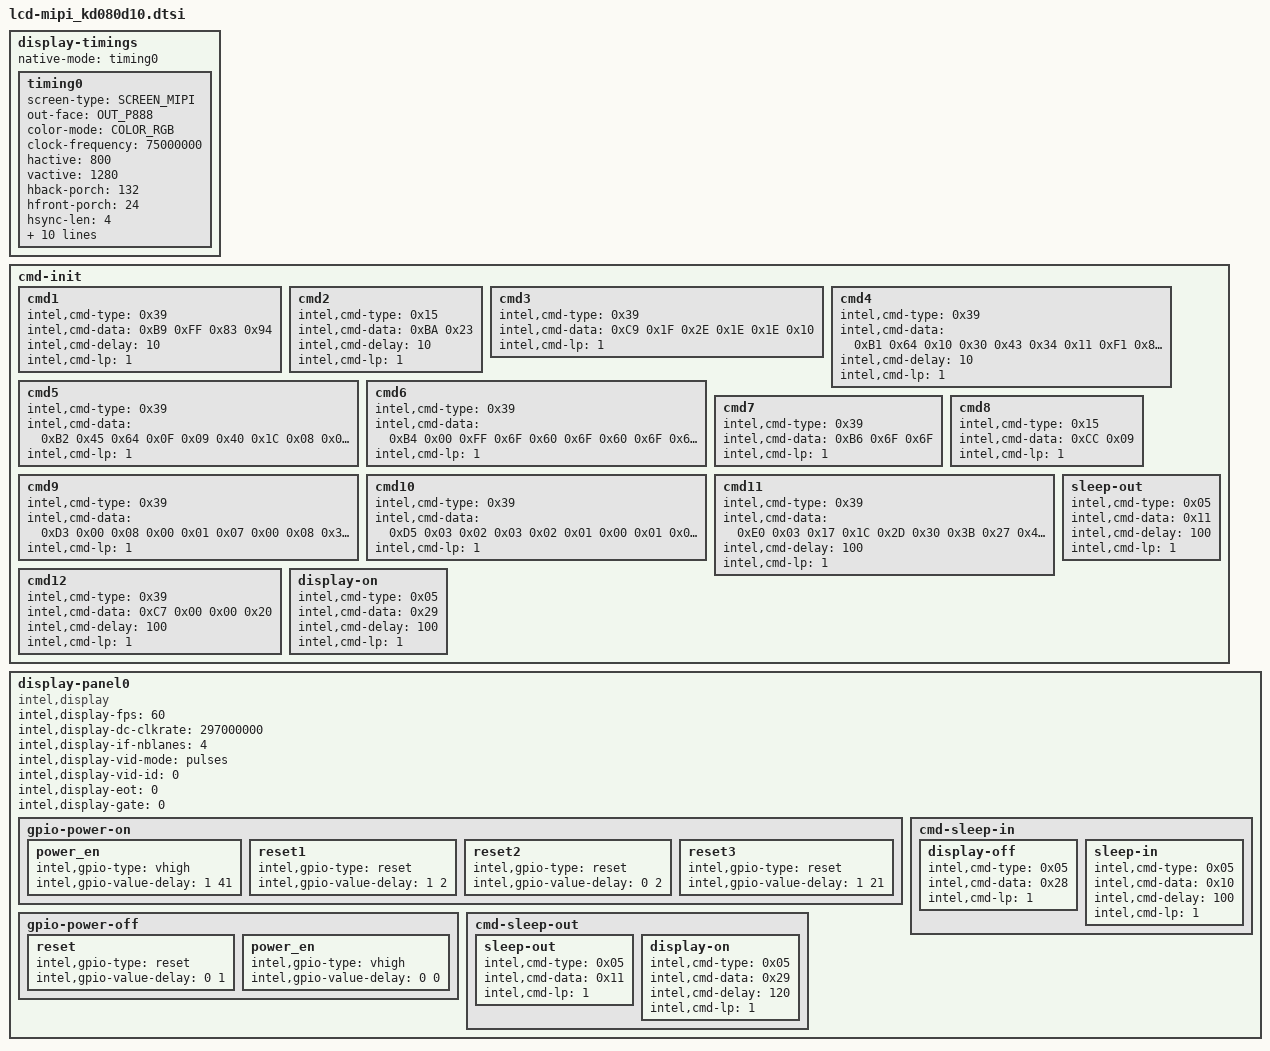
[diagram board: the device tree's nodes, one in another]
/*
 * definition at "include/dt-bindings/sofiafb/sofia_fb.h"
 */

display-timings {
	native-mode = <&timing0>;
	timing0: timing0 {
		screen-type = <SCREEN_MIPI>;
		out-face    = <OUT_P888>;
		color-mode = <COLOR_RGB>;
			clock-frequency = <75000000>;
			hactive = <800>;
			vactive = <1280>;
			hback-porch = <132>;
			hfront-porch = <24>;
			hsync-len = <4>;
			vback-porch = <8>;
			vfront-porch = <8>;
		vsync-len = <4>;
		hsync-active = <0>;
		vsync-active = <0>;
		de-active = <0>;
		pixelclk-active = <0>;
		swap-rb = <0>;
		swap-rg = <0>;
		swap-gb = <0>;
	};
};
		cmd-init {
			cmd1 {
				intel,cmd-type = <0x39>;
				intel,cmd-data = <0xB9 0xFF 0x83 0x94>;
				intel,cmd-delay = <10>;
				intel,cmd-lp = <1>;
			};
						cmd2 {
				intel,cmd-type = <0x15>;
				intel,cmd-data = <0xBA 0x23>;
				intel,cmd-delay = <10>;
				intel,cmd-lp = <1>;
			};
						cmd3 {
				intel,cmd-type = <0x39>;
				intel,cmd-data = <0xC9 0x1F 0x2E 0x1E 0x1E 0x10>;
				intel,cmd-lp = <1>;
			};
						cmd4 {
				intel,cmd-type = <0x39>;
				intel,cmd-data = <0xB1 0x64 0x10 0x30 0x43 0x34 0x11 0xF1 0x81 0x70 0xD9 0x34 0x80 0xC0 0xD2 0x41>;
				intel,cmd-delay = <10>;
				intel,cmd-lp = <1>;
			};
						cmd5 {
				intel,cmd-type = <0x39>;
				intel,cmd-data = <0xB2 0x45 0x64 0x0F 0x09 0x40 0x1C 0x08 0x08 0x1C 0x4D 0x00 0x00>;
				intel,cmd-lp = <1>;
			};
						cmd6 {
				intel,cmd-type = <0x39>;
				intel,cmd-data = <0xB4 0x00 0xFF 0x6F 0x60 0x6F 0x60 0x6F 0x60 0x01 0x6E 0x0F 0x6E 0x6F 0x60 0x6F 0x60 0x6F 0x60 0x01 0x6E 0x0F 0x6E>;
				intel,cmd-lp = <1>;
			};
						cmd7 {
				intel,cmd-type = <0x39>;
				intel,cmd-data = <0xB6 0x6F 0x6F>;
				intel,cmd-lp = <1>;
			};
						cmd8 {
				intel,cmd-type = <0x15>;
				intel,cmd-data = <0xCC 0x09>;
				intel,cmd-lp = <1>;
			};
						cmd9 {
				intel,cmd-type = <0x39>;
				intel,cmd-data = <0xD3 0x00 0x08 0x00 0x01 0x07 0x00 0x08 0x32 0x10 0x0A 0x00 0x05 0x00 0x20 0x0A 0x05 0x09 0x00 0x32 0x10 0x08 0x00 0x35 0x33 0x0D 0x07 0x47 0x0D 0x07 0x47 0x0F 0x08>;
				intel,cmd-lp = <1>;
			};
						cmd10 {
				intel,cmd-type = <0x39>;
				intel,cmd-data = <0xD5 0x03 0x02 0x03 0x02 0x01 0x00 0x01 0x00 0x07 0x06 0x07 0x06 0x05 0x04 0x05 0x04 0x21 0x20 0x18 0x18 0x18 0x18 0x18 0x18 0x18 0x18 0x18 0x18 0x18 0x18 0x23 0x22 0x18 0x18 0x18 0x18 0x18 0x18 0x18 0x18 0x18 0x18 0x18 0x18>;
				intel,cmd-lp = <1>;
			};
						cmd11 {
				intel,cmd-type = <0x39>;
				intel,cmd-data = <0xE0 0x03 0x17 0x1C 0x2D 0x30 0x3B 0x27 0x40 0x08 0x0B 0x0D 0x18 0x0F 0x12 0x15 0x13 0x14 0x07 0x12 0x14 0x17 0x03 0x17 0x1C 0x2D 0x30 0x3B 0x27 0x40 0x08 0x0B 0x0D 0x18 0x0F 0x12 0x15 0x13 0x14 0x07 0x12 0x14 0x17>;
				intel,cmd-delay = <100>;
				intel,cmd-lp = <1>;
			};
						cmd12 {
				intel,cmd-type = <0x39>;
				intel,cmd-data = <0xC7 0x00 0x00 0x20>;
				intel,cmd-delay = <100>;
				intel,cmd-lp = <1>;
			};
			sleep-out {
				intel,cmd-type = <0x05>;
				intel,cmd-data = <0x11>;
				intel,cmd-delay = <100>;
				intel,cmd-lp = <1>;
			};
			display-on {
				intel,cmd-type = <0x05>;
				intel,cmd-data = <0x29>;
				intel,cmd-delay = <100>;
				intel,cmd-lp = <1>;
			};
		
			};
display-panel0{
	compatible = "intel,display";

		/* intel,display-ramless = <1>; */
		intel,display-fps = <60>;
		intel,display-dc-clkrate = <297000000>;
		intel,display-if-nblanes = <4>;
		intel,display-vid-mode = "pulses";
	intel,display-vid-id = <0>;
		intel,display-eot = <0>;
		intel,display-gate = <0>;

	gpio-power-on {
		power_en {
			intel,gpio-type = "vhigh";
			intel,gpio-value-delay = <1 41>;
		};
		reset1 {
			intel,gpio-type = "reset";
			intel,gpio-value-delay = <1 2>;
		};
		reset2 {
			intel,gpio-type = "reset";
			intel,gpio-value-delay = <0 2>;
		};
		reset3 {
			intel,gpio-type = "reset";
			intel,gpio-value-delay = <1 21>;
		};
	};

	gpio-power-off {
		reset {
			intel,gpio-type = "reset";
			intel,gpio-value-delay = <0 1>;
		};
		power_en {
			intel,gpio-type = "vhigh";
			intel,gpio-value-delay = <0 0>;
		};
	};

	cmd-sleep-in {
		display-off {
			intel,cmd-type = <0x05>;
			intel,cmd-data = <0x28>;
			intel,cmd-lp = <1>;
		};
		sleep-in {
			intel,cmd-type = <0x05>;
			intel,cmd-data = <0x10>;
			intel,cmd-delay = <100>;
			intel,cmd-lp = <1>;
		};
	};

	cmd-sleep-out {
		sleep-out {
			intel,cmd-type = <0x05>;
			intel,cmd-data = <0x11>;
			intel,cmd-lp = <1>;
		};
		display-on {
			intel,cmd-type = <0x05>;
			intel,cmd-data = <0x29>;
			intel,cmd-delay = <120>;
			intel,cmd-lp = <1>;
		};
	};
};
